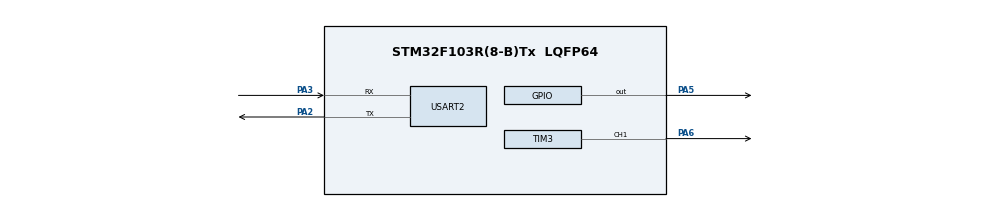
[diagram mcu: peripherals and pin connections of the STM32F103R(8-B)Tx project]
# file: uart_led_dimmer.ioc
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Mcu.Family=STM32F1
Mcu.Name=STM32F103R(8-B)Tx
Mcu.Package=LQFP64
NVIC.PriorityGroup=NVIC_PRIORITYGROUP_4
PA2.Mode=Asynchronous
PA2.Signal=USART2_TX
PA3.Mode=Asynchronous
PA3.Signal=USART2_RX
PA5.Signal=GPIO_Output
PA6.Signal=S_TIM3_CH1
ProjectManager.HeapSize=0x200
ProjectManager.StackSize=0x400
ProjectManager.TargetToolchain=STM32CubeIDE
RCC.APB1Freq_Value=8000000
RCC.APB2Freq_Value=8000000
SH.S_TIM3_CH1.0=TIM3_CH1,PWM Generation1 CH1
TIM3.Channel-PWM\ Generation1\ CH1=TIM_CHANNEL_1
TIM3.Prescaler=72-1
USART2.VirtualMode=VM_ASYNC
VP_SYS_VS_ND.Mode=No_Debug
board=custom

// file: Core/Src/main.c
/* USER CODE BEGIN Header */
/**
  ******************************************************************************
  * @file           : main.c
  * @brief          : Main program body
  ******************************************************************************
  * @attention
  *
  * Copyright (c) 2026 STMicroelectronics.
  * All rights reserved.
  *
  * This software is licensed under terms that can be found in the LICENSE file
  * in the root directory of this software component.
  * If no LICENSE file comes with this software, it is provided AS-IS.
  *
  ******************************************************************************
  */
/* USER CODE END Header */
#include "main.h"

/* USER CODE BEGIN Includes */
#include <stdio.h>
#include <string.h>
#include <stdlib.h>
/* USER CODE END Includes */

TIM_HandleTypeDef htim3;

UART_HandleTypeDef huart2;

/* USER CODE BEGIN PV */
uint8_t rx_buf[32];
/* USER CODE END PV */

void SystemClock_Config(void);
static void MX_GPIO_Init(void);
static void MX_USART2_UART_Init(void);
static void MX_TIM3_Init(void);

/* USER CODE BEGIN 0 */
void set_pwm(uint8_t duty)
{
    if (duty > 100) duty = 100;
    __HAL_TIM_SET_COMPARE(&htim3, TIM_CHANNEL_1, duty);
}
/* USER CODE END 0 */

int main(void)
{

  /* MCU Configuration--------------------------------------------------------*/

  /* Reset of all peripherals, Initializes the Flash interface and the Systick. */
  HAL_Init();

  /* Configure the system clock */
  SystemClock_Config();

  /* Initialize all configured peripherals */
  MX_GPIO_Init();
  MX_USART2_UART_Init();
  MX_TIM3_Init();
  /* USER CODE BEGIN 2 */
  /* Place application initialization code here. */
  char msg[] = "UART LED DIMMER READY>\r\n";
  HAL_UART_Transmit(&huart2, (uint8_t *)msg, strlen(msg), HAL_MAX_DELAY);
  HAL_TIM_PWM_Start(&htim3, TIM_CHANNEL_1);
  /* USER CODE END 2 */

  /* Infinite loop */
  /* USER CODE BEGIN WHILE */
  uint8_t ch;
  uint8_t idx = 0;

  while (1)
  {
      HAL_UART_Receive(&huart2, &ch, 1, HAL_MAX_DELAY);

      if (ch == '\r' || ch == '\n')
      {
          rx_buf[idx] = '\0';

          // 忽略空输入
          if (idx == 0)
          {
              continue;
          }

          // 判断命令
          if (strncmp((char *)rx_buf, "SET ", 4) == 0)
          {
              int val = atoi((char *)&rx_buf[4]);

              if (val >= 0 && val <= 100)
              {
                  set_pwm(val);

                  char resp[32];
                  sprintf(resp, "PWM=%d\r\n", val);
                  HAL_UART_Transmit(&huart2, (uint8_t *)resp, strlen(resp), HAL_MAX_DELAY);
              }
              else
              {
                  char err[] = "Invalid\r\n";
                  HAL_UART_Transmit(&huart2, (uint8_t *)err, strlen(err), HAL_MAX_DELAY);
              }
          }

          // 清空缓冲区
          idx = 0;
          memset(rx_buf, 0, sizeof(rx_buf));

          // 打印提示符
          char msg[] = "READY>\r\n";
          HAL_UART_Transmit(&huart2, (uint8_t *)msg, strlen(msg), HAL_MAX_DELAY);
      }
      else
      {
          if (idx < sizeof(rx_buf) - 1)
          {
              rx_buf[idx++] = ch;
          }
      }
  }
  /* USER CODE END 3 */
}

void SystemClock_Config(void)
{
  RCC_OscInitTypeDef RCC_OscInitStruct = {0};
  RCC_ClkInitTypeDef RCC_ClkInitStruct = {0};

  /** Initializes the RCC Oscillators according to the specified parameters
  * in the RCC_OscInitTypeDef structure.
  */
  RCC_OscInitStruct.OscillatorType = RCC_OSCILLATORTYPE_HSI;
  RCC_OscInitStruct.HSIState = RCC_HSI_ON;
  RCC_OscInitStruct.HSICalibrationValue = RCC_HSICALIBRATION_DEFAULT;
  RCC_OscInitStruct.PLL.PLLState = RCC_PLL_NONE;
  if (HAL_RCC_OscConfig(&RCC_OscInitStruct) != HAL_OK)
  {
    Error_Handler();
  }

  /** Initializes the CPU, AHB and APB buses clocks
  */
  RCC_ClkInitStruct.ClockType = RCC_CLOCKTYPE_HCLK|RCC_CLOCKTYPE_SYSCLK
                              |RCC_CLOCKTYPE_PCLK1|RCC_CLOCKTYPE_PCLK2;
  RCC_ClkInitStruct.SYSCLKSource = RCC_SYSCLKSOURCE_HSI;
  RCC_ClkInitStruct.AHBCLKDivider = RCC_SYSCLK_DIV1;
  RCC_ClkInitStruct.APB1CLKDivider = RCC_HCLK_DIV1;
  RCC_ClkInitStruct.APB2CLKDivider = RCC_HCLK_DIV1;

  if (HAL_RCC_ClockConfig(&RCC_ClkInitStruct, FLASH_LATENCY_0) != HAL_OK)
  {
    Error_Handler();
  }
}

static void MX_TIM3_Init(void)
{

  TIM_MasterConfigTypeDef sMasterConfig = {0};
  TIM_OC_InitTypeDef sConfigOC = {0};

  htim3.Instance = TIM3;
  htim3.Init.Prescaler = 72-1;
  htim3.Init.CounterMode = TIM_COUNTERMODE_UP;
  htim3.Init.Period = 65535;
  htim3.Init.ClockDivision = TIM_CLOCKDIVISION_DIV1;
  htim3.Init.AutoReloadPreload = TIM_AUTORELOAD_PRELOAD_DISABLE;
  if (HAL_TIM_PWM_Init(&htim3) != HAL_OK)
  {
    Error_Handler();
  }
  sMasterConfig.MasterOutputTrigger = TIM_TRGO_RESET;
  sMasterConfig.MasterSlaveMode = TIM_MASTERSLAVEMODE_DISABLE;
  if (HAL_TIMEx_MasterConfigSynchronization(&htim3, &sMasterConfig) != HAL_OK)
  {
    Error_Handler();
  }
  sConfigOC.OCMode = TIM_OCMODE_PWM1;
  sConfigOC.Pulse = 0;
  sConfigOC.OCPolarity = TIM_OCPOLARITY_HIGH;
  sConfigOC.OCFastMode = TIM_OCFAST_DISABLE;
  if (HAL_TIM_PWM_ConfigChannel(&htim3, &sConfigOC, TIM_CHANNEL_1) != HAL_OK)
  {
    Error_Handler();
  }
  HAL_TIM_MspPostInit(&htim3);

}

static void MX_USART2_UART_Init(void)
{

  huart2.Instance = USART2;
  huart2.Init.BaudRate = 115200;
  huart2.Init.WordLength = UART_WORDLENGTH_8B;
  huart2.Init.StopBits = UART_STOPBITS_1;
  huart2.Init.Parity = UART_PARITY_NONE;
  huart2.Init.Mode = UART_MODE_TX_RX;
  huart2.Init.HwFlowCtl = UART_HWCONTROL_NONE;
  huart2.Init.OverSampling = UART_OVERSAMPLING_16;
  if (HAL_UART_Init(&huart2) != HAL_OK)
  {
    Error_Handler();
  }

}

static void MX_GPIO_Init(void)
{
  GPIO_InitTypeDef GPIO_InitStruct = {0};

  /* GPIO Ports Clock Enable */
  __HAL_RCC_GPIOA_CLK_ENABLE();

  /*Configure GPIO pin Output Level */
  HAL_GPIO_WritePin(GPIOA, GPIO_PIN_5, GPIO_PIN_RESET);

  /*Configure GPIO pin : PA5 */
  GPIO_InitStruct.Pin = GPIO_PIN_5;
  GPIO_InitStruct.Mode = GPIO_MODE_OUTPUT_PP;
  GPIO_InitStruct.Pull = GPIO_NOPULL;
  GPIO_InitStruct.Speed = GPIO_SPEED_FREQ_LOW;
  HAL_GPIO_Init(GPIOA, &GPIO_InitStruct);

}

void Error_Handler(void)
{
  __disable_irq();
  while (1)
  {
  }
}
